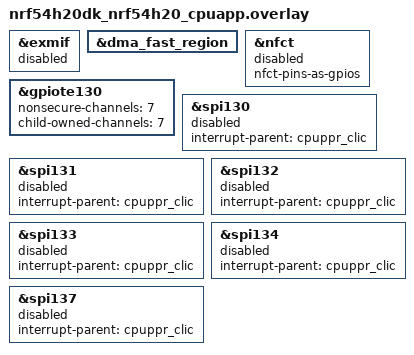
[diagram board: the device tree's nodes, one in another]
/*
 * Copyright (c) 2025 Nordic Semiconductor ASA
 *
 * SPDX-License-Identifier: LicenseRef-Nordic-5-Clause
 */

&exmif {
	status = "disabled";
};

&dma_fast_region {
	status = "okay";
};

&nfct {
	status = "disabled";
	nfct-pins-as-gpios;
};

&gpiote130 {
	nonsecure-channels = < 7 >;
	child-owned-channels = < 7 >;
};

&spi130 {
	status = "reserved";
	interrupt-parent = <&cpuppr_clic>;
};

&spi131 {
	status = "reserved";
	interrupt-parent = <&cpuppr_clic>;
};

&spi132 {
	status = "reserved";
	interrupt-parent = <&cpuppr_clic>;
};

&spi133 {
	status = "reserved";
	interrupt-parent = <&cpuppr_clic>;
};

&spi134 {
	status = "reserved";
	interrupt-parent = <&cpuppr_clic>;
};

/* spi135 inaccessible due to cpuppr console on uart135 */

/* spi136 inaccessible due to cpuapp console on uart136 */

&spi137 {
	status = "reserved";
	interrupt-parent = <&cpuppr_clic>;
};
